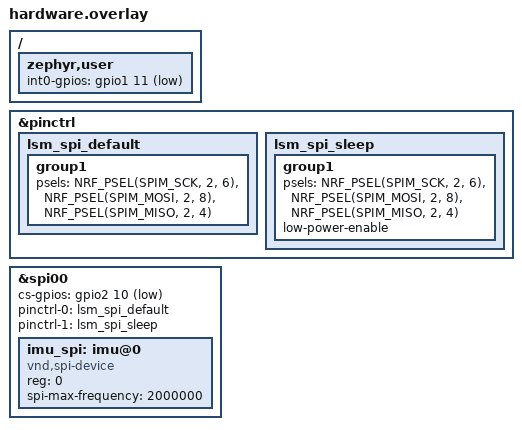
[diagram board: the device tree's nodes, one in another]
/* Apply AFTER wiring.overlay or tracker.overlay, only AFTER rewiring:
 * SCK=P2.06, sensor SDI=P2.08, sensor SDO=P2.04, CS=P2.10, INT1=P1.11.
 */
/delete-node/ &imu_spi;
/delete-node/ &imu_bus;

&pinctrl {
	lsm_spi_default: lsm_spi_default {
		group1 {
			psels = <NRF_PSEL(SPIM_SCK, 2, 6)>,
				<NRF_PSEL(SPIM_MOSI, 2, 8)>,
				<NRF_PSEL(SPIM_MISO, 2, 4)>;
		};
	};
	lsm_spi_sleep: lsm_spi_sleep {
		group1 {
			psels = <NRF_PSEL(SPIM_SCK, 2, 6)>,
				<NRF_PSEL(SPIM_MOSI, 2, 8)>,
				<NRF_PSEL(SPIM_MISO, 2, 4)>;
			low-power-enable;
		};
	};
};

&spi00 {
	status = "okay";
	cs-gpios = <&gpio2 10 GPIO_ACTIVE_LOW>;
	pinctrl-0 = <&lsm_spi_default>;
	pinctrl-1 = <&lsm_spi_sleep>;
	pinctrl-names = "default", "sleep";
	imu_spi: imu@0 {
		compatible = "vnd,spi-device";
		reg = <0>;
		/* SPIM00 has a 128 MHz source and max divider 126: 1 MHz is invalid. */
		spi-max-frequency = <2000000>;
	};
};

/ {
	zephyr,user {
		int0-gpios = <&gpio1 11 GPIO_ACTIVE_LOW>;
	};
};
